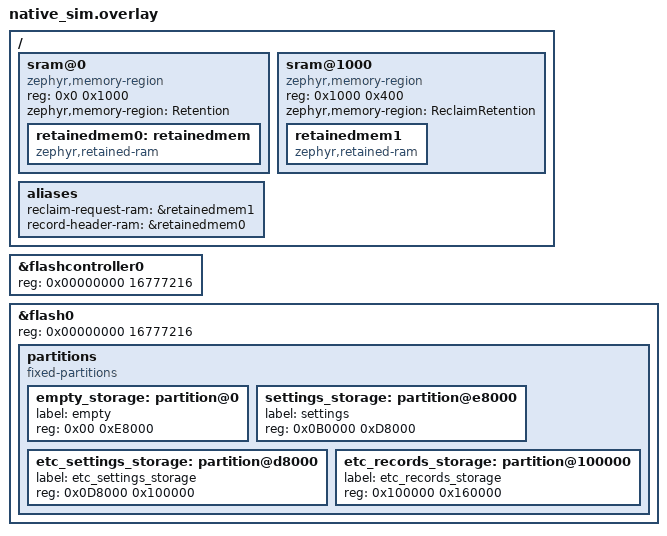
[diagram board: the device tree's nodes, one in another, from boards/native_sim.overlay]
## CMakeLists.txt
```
#SPDX - License - Identifier : Apache - 2.0

cmake_minimum_required(VERSION 3.20.0)
find_package(Zephyr REQUIRED HINTS $ENV{ZEPHYR_BASE})
project(etc_device_record_test)

FILE(GLOB app_sources src/*.c
                      src/mock/*.c
                      src/mock/zephyr/drivers/*.c)
target_sources(app PRIVATE ${app_sources})

set(APP_SRC_DIR ../../../../applications/etc-app/src)

target_compile_options(app PRIVATE -Wno-error=double-promotion)

target_sources(app PRIVATE 
                ${APP_SRC_DIR}/exact/etc_devices/etc_device.c
                ${APP_SRC_DIR}/exact/etc_devices/etc_device_record.c
                ${APP_SRC_DIR}/exact/etc_devices/etc_device_helper.c
                ${APP_SRC_DIR}/exact/etc_memfault/etc_memfault_dummy.c
                ${APP_SRC_DIR}/exact/etc_util/etc_util.c
                ${APP_SRC_DIR}/common.c
)

target_include_directories(app PRIVATE
                            src
                            src/mock
                            src/mock/zephyr/drivers
                            ${APP_SRC_DIR}/exact/etc_battery
                            ${APP_SRC_DIR}/exact/etc_devices
                            ${APP_SRC_DIR}/exact/etc_memfault
                            ${APP_SRC_DIR}/exact/etc_sensor
                            ${APP_SRC_DIR}/exact/etc_settings
                            ${APP_SRC_DIR}/exact/etc_util
                            ${APP_SRC_DIR}/exact/etc_calibration
                            ${APP_SRC_DIR})

zephyr_compile_definitions(IMAGE_HASH_LEN=32)
zephyr_compile_definitions(CONFIG_ETC_APP_LOG_LEVEL=4)
zephyr_compile_definitions(CONFIG_ETC_DEVICE_RELAY_MAX_RECORD_HISTORY=64)
zephyr_compile_definitions(CONFIG_ETC_DEVICE_SAVE_RECORD_SEC=1)
zephyr_compile_definitions(CONFIG_ETC_RECORD_CBOR=1)
```

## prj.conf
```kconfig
CONFIG_ZTEST=y
CONFIG_HEAP_MEM_POOL_SIZE=8192
CONFIG_RETAINED_MEM=y

CONFIG_FLASH=y
CONFIG_FLASH_PAGE_LAYOUT=y
CONFIG_FLASH_MAP=y
CONFIG_NVS=y

# Settings - Used to store real-time device configuration to flash.
CONFIG_SETTINGS=y
CONFIG_SETTINGS_FCB=y
CONFIG_FCB=y

CONFIG_POSIX_API=y

# Application Event Manager
CONFIG_APP_EVENT_MANAGER=y
CONFIG_APP_EVENT_MANAGER_LOG_EVENT_TYPE=n

CONFIG_REQUIRES_FLOAT_PRINTF=y

CONFIG_ZCBOR=y
CONFIG_ZCBOR_CANONICAL=y
```

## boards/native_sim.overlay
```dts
/ {
	sram@0 {
		compatible = "zephyr,memory-region";
		reg = <0x0 0x1000>;
		status = "okay";
		zephyr,memory-region = "Retention";

		retainedmem0: retainedmem {
			compatible = "zephyr,retained-ram";
			status = "okay";
		};
	};

	sram@1000 {
		compatible = "zephyr,memory-region";
		reg = <0x1000 0x400>;
		status = "okay";
		zephyr,memory-region = "ReclaimRetention";

		retainedmem1: retainedmem1 {
			compatible = "zephyr,retained-ram";
			status = "okay";
		};
	};

	aliases {
		reclaim-request-ram = &retainedmem1;
		record-header-ram = &retainedmem0;
	};
};

&flashcontroller0 {
	reg = <0x00000000 16777216>;
};

&flash0 {
	reg = <0x00000000 16777216>;

	partitions {
		compatible = "fixed-partitions";
		#address-cells = <1>;
		#size-cells = <1>;

		/delete-node/ boot_partition;
		/delete-node/ slot0_partition;
		/delete-node/ slot1_partition;
		/delete-node/ scratch_partition;
		/delete-node/ storage_partition;

		empty_storage: partition@0 {
			label = "empty";
			reg = < 0x00 0xE8000 >;
		};
		settings_storage: partition@e8000 {
			label = "settings";
			reg = < 0x0B0000 0xD8000 >;
		};
		etc_settings_storage: partition@d8000 {
			label = "etc_settings_storage";
			reg = < 0x0D8000 0x100000 >;
		};
		etc_records_storage: partition@100000 {
			label = "etc_records_storage";
			reg = < 0x100000 0x160000 >;
		};
	};
};
```

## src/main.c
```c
/*
 * Copyright (c) 2025 EXACT Technology Corporation
 */

#include <stdbool.h>
#include <string.h>
#include <zephyr/ztest.h>
#include <math.h>
#include "etc_device.h"
#include "etc_device_record.h"
#include "etc_util.h"
#include "etc_device_helper.h"
#include <zephyr/logging/log.h>

LOG_MODULE_REGISTER(etc_device_record_test, CONFIG_ETC_APP_LOG_LEVEL);

#define EPSILON 0.01f

static void *test_setup(void)
{
	return NULL;
}

static void test_teardown(void *)
{
}

static void etc_device_helper_common_test(struct sensor_data *original)
{

	uint8_t buf[256];
	size_t buf_len = sizeof(buf);

	int ret = etc_device_encode_cbor_data(original, buf, &buf_len);
	zassert_equal(ret, 0);

	buf_len = sizeof(buf);
	struct sensor_data decoded = {0};
	ret = etc_device_decode_cbor_data(&decoded, buf, buf_len);
	zassert_equal(ret, 0);

	zassert_equal(original->timestamp, decoded.timestamp);
	zassert_equal(original->battery_mV, decoded.battery_mV);

	for (int i = 0; i <= SENSOR_INPUT_AMBIENT; i++) {
		if (sensor_temperature_is_valid(original->sensor[i])) {
			ret = (fabsf((double)(original->sensor[i] - decoded.sensor[i])) < EPSILON);
			zassert_equal(ret, 1);
		}
	}

	if (sensor_humidity_is_valid(original->sensor[SENSOR_INPUT_HUMID])) {
		ret = (fabsf((double)(original->sensor[SENSOR_INPUT_HUMID] -
				      decoded.sensor[SENSOR_INPUT_HUMID])) < EPSILON);
		zassert_equal(ret, 1);
	}
}

ZTEST(etc_device_helper_test, test_case)
{
	struct sensor_data test_data_1 = {
		.timestamp = 1234567890,
		.battery_mV = 3800,
		.sensor = {25.5f, 26.0f, 26.5f, 27.0f, 27.5f, 27.5f, 27.5f, 27.5f, 27.5f, 80.0f},
		.battery_status = 1};

	struct sensor_data test_data_2 = {
		.timestamp = 1234567890,
		.battery_mV = 3800,
		.sensor = {25.5f, -31.0f, 120.5f, 27.0f, 27.5f, 27.5f, 27.5f, 27.5f, 27.5f, 80.0f},
		.battery_status = 1};

	struct sensor_data test_data_3 = {
		.timestamp = 1234567890,
		.battery_mV = 3800,
		.sensor = {25.5f, -31.0f, 120.5f, 27.0f, 27.5f, 27.5f, 27.5f, 27.5f, 27.5f, 110.0f},
		.battery_status = 1};

	struct sensor_data test_data_4 = {
		.timestamp = 1234567890,
		.battery_mV = 3800,
		.sensor = {25.5f, -31.0f, 120.5f, 27.0f, 27.5f, 27.5f, 27.5f, 27.5f, 27.5f, -1.0f},
		.battery_status = 1};

	struct sensor_data test_data_5 = {.timestamp = 1234567890,
					  .battery_mV = 3800,
					  .sensor = {-31.0f, -31.0f, -31.0f, -31.0f, -31.0f, 27.5f,
						     27.5f, 27.5f, 27.5f, -1.0f},
					  .battery_status = 1};

	etc_device_helper_common_test(&test_data_1);
	etc_device_helper_common_test(&test_data_2);
	etc_device_helper_common_test(&test_data_3);
	etc_device_helper_common_test(&test_data_4);
	etc_device_helper_common_test(&test_data_5);
}

ZTEST_SUITE(etc_device_helper_test, NULL, test_setup, NULL, NULL, test_teardown);
```
